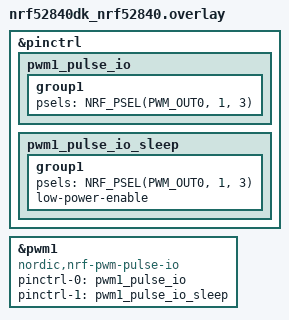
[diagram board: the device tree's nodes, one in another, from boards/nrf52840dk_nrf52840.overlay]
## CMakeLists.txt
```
# Copyright (c) 2026 Espressif Systems (Shanghai) Co., Ltd.
# SPDX-License-Identifier: Apache-2.0

cmake_minimum_required(VERSION 3.28.0)
find_package(Zephyr REQUIRED HINTS $ENV{ZEPHYR_BASE})
project(pulse_io_api)

target_sources(app PRIVATE src/main.c)
target_sources_ifdef(CONFIG_PULSE_IO_NRF_PWM app PRIVATE src/nrf_pwm.c)
```

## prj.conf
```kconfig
CONFIG_ZTEST=y
CONFIG_PULSE_IO=y
```

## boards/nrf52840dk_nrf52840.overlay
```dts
/*
 * SPDX-FileCopyrightText: Copyright The Zephyr Project Contributors
 * Copyright (c) 2026 Dev It Wise
 *
 * SPDX-License-Identifier: Apache-2.0
 */

&pinctrl {
	pwm1_pulse_io: pwm1_pulse_io {
		group1 {
			psels = <NRF_PSEL(PWM_OUT0, 1, 3)>;
		};
	};

	pwm1_pulse_io_sleep: pwm1_pulse_io_sleep {
		group1 {
			psels = <NRF_PSEL(PWM_OUT0, 1, 3)>;
			low-power-enable;
		};
	};
};

pulse_io0: &pwm1 {
	compatible = "nordic,nrf-pwm-pulse-io";
	#pulse-io-cells = <1>;
	pinctrl-0 = <&pwm1_pulse_io>;
	pinctrl-1 = <&pwm1_pulse_io_sleep>;
	pinctrl-names = "default", "sleep";
	status = "okay";
};
```

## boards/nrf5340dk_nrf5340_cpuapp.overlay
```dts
/*
 * SPDX-FileCopyrightText: Copyright The Zephyr Project Contributors
 * Copyright (c) 2026 Dev It Wise
 *
 * SPDX-License-Identifier: Apache-2.0
 */

&pinctrl {
	pwm1_pulse_io: pwm1_pulse_io {
		group1 {
			psels = <NRF_PSEL(PWM_OUT0, 1, 13)>;
		};
	};

	pwm1_pulse_io_sleep: pwm1_pulse_io_sleep {
		group1 {
			psels = <NRF_PSEL(PWM_OUT0, 1, 13)>;
			low-power-enable;
		};
	};
};

pulse_io0: &pwm1 {
	compatible = "nordic,nrf-pwm-pulse-io";
	#pulse-io-cells = <1>;
	pinctrl-0 = <&pwm1_pulse_io>;
	pinctrl-1 = <&pwm1_pulse_io_sleep>;
	pinctrl-names = "default", "sleep";
	status = "okay";
};
```

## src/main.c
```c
/*
 * Copyright (c) 2026 Espressif Systems (Shanghai) Co., Ltd.
 *
 * SPDX-License-Identifier: Apache-2.0
 */

#include <zephyr/ztest.h>
#include <zephyr/drivers/pulse_io.h>

static const struct device *dev = DEVICE_DT_GET(DT_NODELABEL(pulse_io0));

ZTEST(pulse_io_api, test_device_ready)
{
	zassert_true(device_is_ready(dev), "pulse_io device not ready");
}

#if DT_NODE_HAS_COMPAT(DT_NODELABEL(pulse_io0), zephyr_pulse_io_loopback)
ZTEST(pulse_io_api, test_capabilities)
{
	struct pulse_io_caps caps;

	zassert_ok(pulse_io_get_capabilities(dev, &caps));
	zassert_true(caps.modes & PULSE_IO_MODE_SYMBOL);
	zassert_true(caps.supports_tx);
	zassert_true(caps.supports_rx);
	zassert_equal(caps.num_channels, 4);
	zassert_equal(caps.tx_channel_mask, BIT_MASK(4));
	zassert_equal(caps.rx_channel_mask, BIT_MASK(4));
}
#endif

ZTEST(pulse_io_api, test_channel_lifecycle)
{
	struct pulse_io_channel *ch;

	zassert_ok(pulse_io_channel_get(dev, 0, &ch));
	zassert_not_null(ch);
	struct pulse_io_channel *again;

	zassert_equal(pulse_io_channel_get(dev, 0, &again), -EBUSY);
	zassert_ok(pulse_io_channel_release(dev, ch));
	zassert_equal(pulse_io_channel_get(dev, 99, &ch), -ENODEV);
}

#if DT_NODE_HAS_COMPAT(DT_NODELABEL(pulse_io0), zephyr_pulse_io_loopback)
ZTEST(pulse_io_api, test_configure_rejects_bad_mode)
{
	struct pulse_io_channel *ch;
	struct pulse_io_config cfg = {
		.mode = (enum pulse_io_mode)0xFF,
		.dir = PULSE_IO_DIR_TX,
		.resolution_hz = 1000000,
	};

	zassert_ok(pulse_io_channel_get(dev, 1, &ch));
	zassert_equal(pulse_io_channel_configure(dev, ch, &cfg), -ENOTSUP);
	zassert_ok(pulse_io_channel_release(dev, ch));
}

ZTEST(pulse_io_api, test_transmit_receive_roundtrip)
{
	struct pulse_io_channel *ch;
	struct pulse_io_config cfg = {
		.mode = PULSE_IO_MODE_SYMBOL,
		.dir = PULSE_IO_DIR_TX,
		.resolution_hz = 1000000,
	};
	struct pulse_symbol tx[] = {
		{.duration = 100, .level = 1},
		{.duration = 200, .level = 0},
		{.duration = 300, .level = 1},
	};
	struct pulse_symbol rx[8];
	size_t count = 0;

	zassert_ok(pulse_io_channel_get(dev, 2, &ch));
	zassert_ok(pulse_io_channel_configure(dev, ch, &cfg));

	struct pulse_io_tx_req txr = {.symbols = tx, .count = ARRAY_SIZE(tx)};

	zassert_ok(pulse_io_transmit_sync(dev, ch, &txr, K_MSEC(10)));

	struct pulse_io_rx_req rxr = {.symbols = rx, .capacity = ARRAY_SIZE(rx)};

	zassert_ok(pulse_io_receive_sync(dev, ch, &rxr, &count, K_MSEC(10)));
	zassert_equal(count, ARRAY_SIZE(tx), "wrong symbol count");

	for (size_t i = 0; i < count; i++) {
		zassert_equal(rx[i].duration, tx[i].duration, "duration[%zu]", i);
		zassert_equal(rx[i].level, tx[i].level, "level[%zu]", i);
	}

	zassert_ok(pulse_io_stop(dev, ch));
	zassert_ok(pulse_io_channel_release(dev, ch));
}
#endif

/* Bit template shared by the codec tests: zero = short high, one = long. */
#define CODEC_T 4U
static const struct pulse_io_bit_template codec_tmpl = {
	.zero = {{CODEC_T, 1}, {3 * CODEC_T, 0}},
	.one = {{3 * CODEC_T, 1}, {CODEC_T, 0}},
	.msb_first = true,
};

ZTEST(pulse_io_api, test_encode_exact_layout)
{
	/* 0x80 MSB-first: bit 7 = 1, bits 6..0 = 0. */
	const uint8_t in = 0x80;
	struct pulse_symbol out[8 * 2];
	size_t produced = 0;

	zassert_ok(pulse_io_encode_bytes(&codec_tmpl, &in, 1, out, ARRAY_SIZE(out), &produced));
	zassert_equal(produced, 16, "wrong symbol count");

	/* First bit is a one: long high then short low. */
	zassert_equal(out[0].duration, 3 * CODEC_T);
	zassert_equal(out[0].level, 1);
	zassert_equal(out[1].duration, CODEC_T);
	zassert_equal(out[1].level, 0);

	/* Second bit is a zero: short high then long low. */
	zassert_equal(out[2].duration, CODEC_T);
	zassert_equal(out[2].level, 1);
	zassert_equal(out[3].duration, 3 * CODEC_T);
}

ZTEST(pulse_io_api, test_encode_decode_lsb_first)
{
	struct pulse_io_bit_template lsb = codec_tmpl;

	lsb.msb_first = false;

	const uint8_t msg[] = {0x35, 0xC2};
	struct pulse_symbol syms[sizeof(msg) * 8 * 2];
	uint8_t decoded[sizeof(msg)];
	size_t produced = 0;

	zassert_ok(
		pulse_io_encode_bytes(&lsb, msg, sizeof(msg), syms, ARRAY_SIZE(syms), &produced));
	zassert_ok(pulse_io_decode_bytes(&lsb, CODEC_T - 1U, syms, produced, decoded,
					 sizeof(decoded), &produced));
	zassert_equal(produced, sizeof(msg));
	zassert_mem_equal(decoded, msg, sizeof(msg), "LSB-first round-trip mismatch");
}

ZTEST(pulse_io_api, test_decode_rejects_garbage)
{
	struct pulse_symbol bad[2] = {
		{.duration = 999, .level = 1}, /* matches neither one nor zero */
		{.duration = 999, .level = 0},
	};
	uint8_t out[1];
	size_t produced = 0;

	zassert_equal(pulse_io_decode_bytes(&codec_tmpl, 1, bad, 16, out, sizeof(out), &produced),
		      -EILSEQ, "garbage should be rejected");
}

ZTEST(pulse_io_api, test_codec_arg_errors)
{
	uint8_t in = 0xAA;
	struct pulse_symbol out[16];
	size_t produced = 0;

	/* NULL args. */
	zassert_equal(pulse_io_encode_bytes(NULL, &in, 1, out, ARRAY_SIZE(out), &produced),
		      -EINVAL);
	/* Output buffer too small (need 16, give 4). */
	zassert_equal(pulse_io_encode_bytes(&codec_tmpl, &in, 1, out, 4, &produced), -ENOMEM);
}

ZTEST(pulse_io_api, test_cell_mode_config)
{
	struct pulse_io_channel *ch;
	struct pulse_io_config cfg = {
		.mode = PULSE_IO_MODE_CELL,
		.dir = PULSE_IO_DIR_TX,
		.resolution_hz = 1000000,
	};

	zassert_ok(pulse_io_channel_get(dev, 0, &ch));

	/* CELL with zero period is rejected. */
	cfg.cell_period_ticks = 0;
	zassert_equal(pulse_io_channel_configure(dev, ch, &cfg), -EINVAL);

	/* CELL with a valid period is accepted. */
	cfg.cell_period_ticks = 20000;
	zassert_ok(pulse_io_channel_configure(dev, ch, &cfg));

	zassert_ok(pulse_io_channel_release(dev, ch));
}

#if DT_NODE_HAS_COMPAT(DT_NODELABEL(pulse_io0), zephyr_pulse_io_loopback)
ZTEST(pulse_io_api, test_transmit_sync_rejects_infinite_loop)
{
	struct pulse_io_channel *ch;
	struct pulse_io_config cfg = {
		.mode = PULSE_IO_MODE_SYMBOL,
		.dir = PULSE_IO_DIR_TX,
		.resolution_hz = 1000000,
	};
	struct pulse_symbol sym = {.duration = 100, .level = 1};
	struct pulse_io_tx_req req = {
		.symbols = &sym,
		.count = 1,
		.loop_count = UINT32_MAX, /* infinite */
	};

	zassert_ok(pulse_io_channel_get(dev, 1, &ch));
	zassert_ok(pulse_io_channel_configure(dev, ch, &cfg));
	zassert_equal(pulse_io_transmit_sync(dev, ch, &req, K_MSEC(10)), -ENOTSUP,
		      "infinite loop must be rejected by sync transmit");
	zassert_ok(pulse_io_channel_release(dev, ch));
}
#endif

ZTEST_SUITE(pulse_io_api, NULL, NULL, NULL, NULL, NULL);
```

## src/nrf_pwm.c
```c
/*
 * SPDX-FileCopyrightText: Copyright The Zephyr Project Contributors
 * Copyright (c) 2026 Dev It Wise
 *
 * SPDX-License-Identifier: Apache-2.0
 */

#include <zephyr/ztest.h>
#include <zephyr/drivers/pulse_io.h>

#define CELL_PERIOD_TICKS 13U
#define FRAME_CELLS       24U

static const struct device *pwm_dev = DEVICE_DT_GET(DT_NODELABEL(pulse_io0));
static struct pulse_io_channel *pwm_chan;

static const struct pulse_io_config cell_tx_cfg = {
	.resolution_hz = 10000000U,
	.cell_period_ticks = CELL_PERIOD_TICKS,
	.mode = PULSE_IO_MODE_CELL,
	.dir = PULSE_IO_DIR_TX,
};

static void pulse_io_nrf_pwm_after(void *fixture)
{
	struct pulse_io_channel *held = pwm_chan;

	ARG_UNUSED(fixture);

	if (held == NULL) {
		return;
	}

	pwm_chan = NULL;
	zassert_ok(pulse_io_channel_release(pwm_dev, held));
}

ZTEST(pulse_io_nrf_pwm, test_capabilities)
{
	struct pulse_io_caps caps;

	zassert_ok(pulse_io_get_capabilities(pwm_dev, &caps));
	zassert_equal(caps.modes, PULSE_IO_MODE_CELL);
	zassert_true(caps.supports_tx);
	zassert_false(caps.supports_rx);
	zassert_equal(caps.num_channels, 1U);
	zassert_equal(caps.tx_channel_mask, BIT(0));
	zassert_equal(caps.rx_channel_mask, 0U);
	zassert_equal(caps.tx_max_streaming, CONFIG_PULSE_IO_NRF_PWM_CELLS);
	zassert_equal(caps.cell_duty_bits, 15U);
}

ZTEST(pulse_io_nrf_pwm, test_channel_index)
{
	zassert_equal(pulse_io_channel_get(pwm_dev, 1, &pwm_chan), -ENODEV);
}

ZTEST(pulse_io_nrf_pwm, test_configure_refusals)
{
	struct pulse_io_config cfg = {
		.resolution_hz = 1000U,
		.cell_period_ticks = 262U,
		.mode = PULSE_IO_MODE_SYMBOL,
		.dir = PULSE_IO_DIR_TX,
	};

	zassert_ok(pulse_io_channel_get(pwm_dev, 0, &pwm_chan));
	zassert_equal(pulse_io_channel_configure(pwm_dev, pwm_chan, &cfg), -ENOTSUP);

	cfg.mode = PULSE_IO_MODE_CELL;
	cfg.dir = PULSE_IO_DIR_RX;
	zassert_equal(pulse_io_channel_configure(pwm_dev, pwm_chan, &cfg), -ENOTSUP);

	cfg.dir = PULSE_IO_DIR_TX;
	cfg.carrier_en = true;
	zassert_equal(pulse_io_channel_configure(pwm_dev, pwm_chan, &cfg), -ENOTSUP);

	cfg.carrier_en = false;
	cfg.cell_period_ticks = 263U;
	zassert_equal(pulse_io_channel_configure(pwm_dev, pwm_chan, &cfg), -EINVAL);

	cfg.cell_period_ticks = 262U;
	zassert_ok(pulse_io_channel_configure(pwm_dev, pwm_chan, &cfg));
}

ZTEST(pulse_io_nrf_pwm, test_transmit_cells)
{
	struct pulse_cell cells[FRAME_CELLS];
	struct pulse_io_tx_req req = {.cells = cells, .count = ARRAY_SIZE(cells)};

	for (size_t i = 0U; i < ARRAY_SIZE(cells); i++) {
		cells[i] = (struct pulse_cell){.duty = ((i % 2U) == 0U) ? 4U : 9U};
	}

	zassert_ok(pulse_io_channel_get(pwm_dev, 0, &pwm_chan));
	zassert_ok(pulse_io_channel_configure(pwm_dev, pwm_chan, &cell_tx_cfg));
	zassert_ok(pulse_io_transmit_sync(pwm_dev, pwm_chan, &req, K_MSEC(10)));

	cells[FRAME_CELLS - 1U].duty = CELL_PERIOD_TICKS + 1U;
	zassert_equal(pulse_io_transmit_sync(pwm_dev, pwm_chan, &req, K_MSEC(10)), -EINVAL);

	cells[FRAME_CELLS - 1U].duty = 9U;
	zassert_ok(pulse_io_transmit_sync(pwm_dev, pwm_chan, &req, K_MSEC(10)));
}

ZTEST(pulse_io_nrf_pwm, test_transmit_refusals)
{
	static struct pulse_cell oversized[CONFIG_PULSE_IO_NRF_PWM_CELLS + 1U];
	struct pulse_io_tx_req req = {.cells = oversized};

	zassert_ok(pulse_io_channel_get(pwm_dev, 0, &pwm_chan));
	zassert_ok(pulse_io_channel_configure(pwm_dev, pwm_chan, &cell_tx_cfg));

	req.count = 0U;
	zassert_equal(pulse_io_transmit_sync(pwm_dev, pwm_chan, &req, K_MSEC(10)), -EINVAL);

	req.count = ARRAY_SIZE(oversized);
	zassert_equal(pulse_io_transmit_sync(pwm_dev, pwm_chan, &req, K_MSEC(10)), -ENOMEM);

	req.count = 1U;
	req.loop_count = 1U;
	zassert_equal(pulse_io_transmit_sync(pwm_dev, pwm_chan, &req, K_MSEC(10)), -ENOTSUP);
}

ZTEST(pulse_io_nrf_pwm, test_receive)
{
	struct pulse_cell cells[1];
	struct pulse_io_rx_req req = {.cells = cells, .capacity = ARRAY_SIZE(cells)};
	size_t count = 0U;

	zassert_ok(pulse_io_channel_get(pwm_dev, 0, &pwm_chan));
	zassert_equal(pulse_io_receive_sync(pwm_dev, pwm_chan, &req, &count, K_MSEC(10)), -ENOTSUP);
}

ZTEST_SUITE(pulse_io_nrf_pwm, NULL, NULL, NULL, pulse_io_nrf_pwm_after, NULL);
```
